# USB0_COMMON_0_VBP2APB_WRAP_CONTROLLER_VBP_CORE_ADDR_MAP register map
Vendor: Texas Instruments
Registers are 32-bit, access per field, reset 0x0 unless marked. A register's access mark holds for its fields unless they carry their own. Offsets are as the file gives them; [hi:lo] are bit positions; {n}, {i} and the like mark numbered series.

## USB0_COMMON_0_VBP2APB_WRAP_CONTROLLER_VBP_CORE_ADDR_MAP (part 7 of 8)
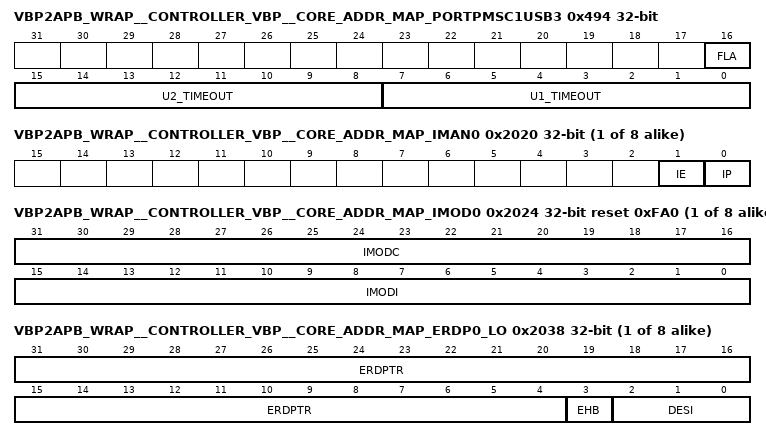
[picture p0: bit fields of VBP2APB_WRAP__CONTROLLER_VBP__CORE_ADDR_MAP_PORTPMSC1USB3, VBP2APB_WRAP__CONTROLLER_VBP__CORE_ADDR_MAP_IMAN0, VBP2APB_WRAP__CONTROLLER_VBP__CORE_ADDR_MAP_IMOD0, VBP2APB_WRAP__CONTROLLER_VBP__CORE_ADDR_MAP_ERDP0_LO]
0x494 VBP2APB_WRAP__CONTROLLER_VBP__CORE_ADDR_MAP_PORTPMSC1USB3
  [16] FLA rw — Force Link PM Accept [FLA], RW. Default = '0'. When this bit is set to '1', the port shall generate a Set Link Function LMP with the Force_LinkPM_Accept bit asserted ['1']. When this bit is cleared to '0', the port shall generate a Set Link Function LMP with the Force_LinkPM_Accept bit de-asserted ['0']. This flag shall be set to '0' by the assertion of PR to '1' or when CCS = transitions from '0' to '1'. Writes to this flag have no effect if PP = '0'. The Set Link Function LMP is sent by the xHC to the device connected on this port when this bit transitions from '0' to '1' or '1' to '0'. Refer to Sections 8.4.2 and 10.14.2.2 of the USB3 specification for more details. Improper use of the SS Force_LinkPM_Accept functionality can impact the performance of the link significantly. This bit shall only be used for compliance and testing purposes. Software shall ensure that there are no pending packets at the link level before setting this bit. This flag is '0' if PP is '0'.
  [15:8] U2_TIMEOUT rw — U2 Timeout, RWS. Default = 0. Timeout value for U2 inactivity timer. If equal to FFh, the port is disabled from initiating U2 entry. This field shall be set to '0' by the assertion of PR to '1'. Refer to section 4.19.4.1 of xHCI specification for more information on U2 Timeout operation. The following are permissible values: 00h Zero [default] 01h 256 us 02h 512 us ... FEh 65,.024 ms FFh Infinite A U2 Inactivity Timeout LMP shall be sent by the xHC to the device connected on this port when this field is written. Refer to Sections 8.4.3 and 10.4.2.10 of the USB3 specification for more details.
  [7:0] U1_TIMEOUT rw — U1 Timeout, RWS. Default = 0. Timeout value for U1 inactivity timer. If equal to FFh, the port is disabled from initiating U1 entry. This field shall be set to '0' by the assertion of PR to '1'. Refer to section 4.19.4.1 of xHCI specification for more information on U1 Timeout operation. The following are permissible values: 00h Zero [default] 01h 1 us. 02h 2 us. ... 7Fh 127 us. 80h - FEh Reserved FFh Infinite
0x498 VBP2APB_WRAP__CONTROLLER_VBP__CORE_ADDR_MAP_PORTLI1 ro
  [15:0] LEC — Link Error Count, RO. Default = '0'. This field returns the number of link errors detected by the port. This value shall be reset to '0' by the assertion of a Chip Hardware Reset, HCRST, when PR transitions from 1 to 0, or when CCS = transitions from '0' to '1'.
0x49C VBP2APB_WRAP__CONTROLLER_VBP__CORE_ADDR_MAP_RSVDP1USB3 ro
0x2000 VBP2APB_WRAP__CONTROLLER_VBP__CORE_ADDR_MAP_MFINDEX ro
  [13:0] MFINDEX — Microframe Index, RO. The value in this register increments at the end of each microframe [e.g. 125us.]. Bits [13:3] may be used to determine the current 1ms Frame Index. Note: Setting frindex_wr_en to '1' [bit 31 of XECP_CMDM_CTRL_REG3] enables software writes to this field.
0x2004 VBP2APB_WRAP__CONTROLLER_VBP__CORE_ADDR_MAP_RSVDZ_RT ro
{0x2020+0x20*i} VBP2APB_WRAP__CONTROLLER_VBP__CORE_ADDR_MAP_IMAN{i} access not given (i=0..7)
  [1] IE rw — Interrupt Enable [IE], RW. Default = '0'. This flag specifies whether the Interrupter is capable of generating an interrupt. When this bit and the IP bit are set ['1'], the Interrupter shall generate an interrupt when the Interrupter Moderation Counter reaches 0. If this bit is '0', then the Interrupter is prohibited from generating interrupts.
  [0] IP — Interrupt Pending [IP], RW1C. Default = '0'. This flag represents the current state of the Interrupter. If IP = '1', an interrupt is pending for this Interrupter. A '0' value indicates that no interrupt is pending for the Interrupter. Refer to section 4.17.5 of the xHCI specification for the conditions that modify the state of this flag. (access R/W1TC)
{0x2024+0x20*i} VBP2APB_WRAP__CONTROLLER_VBP__CORE_ADDR_MAP_IMOD{i} rw reset 0xFA0 (i=0..7)
  [31:16] IMODC — Interrupt Moderation Counter [IMODC], RW. Default = undefined. Down counter. Loaded with the IMODI value whenever IP is cleared to '0', counts down to 0, and stops. The associated interrupt shall be signaled whenever this counter is zero, the Event Ring is not empty, the IE and IP flags = '1', and EHB = '0'. This counter may be directly written by software at any time to alter the interrupt rate.
  [15:0] IMODI — Interrupt Moderation Interval [IMODI], RW. Default = 'hFA0' [~1ms]. Minimum inter-interrupt interval. The interval is specified in 250ns increments. A value of zero disables interrupt throttling logic and interrupts shall be generated immediately if IP = '0', EHB = '0', and the Event Ring is not empty. The IMODI field shall default to 'hFA0' [1 ms] upon initialization and reset. It may be loaded with an alternative value by software when the Interrupter is initialized.
{0x2028+0x20*i} VBP2APB_WRAP__CONTROLLER_VBP__CORE_ADDR_MAP_ERSTSZ{i} (i=0..7)
  [15:0] ERSTS rw — Event Ring Segment Table Size, RW. Default = 0. This field identifies the number of valid Event Ring Segment Table entries in the Event Ring Segment Table pointed to by the Event Ring Segment Table Base Address register. The maximum value supported by an xHC implementation for this register is defined by the ERST Max field in the HCSPARAMS2 register. For Secondary Interrupters: Writing a value of 0 to this field disables the Event Ring. Any events targeted at this Event Ring when it is disabled shall result in undefined behavior of the Event Ring. For the Primary Interrupter: Writing a value of 0 to this field shall result in undefined behavior of the Event Ring. The Primary Event Ring cannot be disabled.
{0x202C+0x20*i} VBP2APB_WRAP__CONTROLLER_VBP__CORE_ADDR_MAP_reserved{i} ro (i=0..7)
{0x2030+0x20*i} VBP2APB_WRAP__CONTROLLER_VBP__CORE_ADDR_MAP_ERSTBA{i}_LO (i=0..7)
  [31:6] ERSTBADDR_LO rw — Event Ring Segment Table Base Address Register, RW. Default = 0. This field defines the low order bit [25:0] of the start address of the Event Ring Segment Table [the address is 58 bits wide] . Writing this register sets the Event Ring State Machine: EREP Advancement to the Start state. This field shall not be modified if HCHalted [HCH] = '0'.
{0x2034+0x20*i} VBP2APB_WRAP__CONTROLLER_VBP__CORE_ADDR_MAP_ERSTBA{i}_HI rw (i=0..7)
  [31:0] ERSTBADDR_HI — Event Ring Segment Table Base Address Register, RW. Default = 0. This field defines the high order bits [57:26] of the start address of the Event Ring Segment Table [the address is 58 bits wide] . Writing this register sets the Event Ring State Machine:EREP Advancement to the Start state. Refer to Figure 20 in xHCI specificationfor more information. This field shall not be modified if HCHalted [HCH] = '0'.
{0x2038+0x20*i} VBP2APB_WRAP__CONTROLLER_VBP__CORE_ADDR_MAP_ERDP{i}_LO access not given (i=0..7)
  [31:4] ERDPTR rw — Event Ring Dequeue Pointer, RW. Default = 0. This field defines the 28 low order bits of the 64-bit address of the current Event Ring Dequeue Pointer.
  [3] EHB — Event Handler Busy [EHB], RW1C. Default = '0'. This flag shall be set to '1' when the IP bit is set to '1' and cleared to '0' by software when the Dequeue Pointer register is written. Refer to section 4.17.2 of xHCI specification for more information (access R/W1TC)
  [2:0] DESI rw — Dequeue ERST Segment Index [DESI]. Default = 0. This field may be used by the xHC to accelerate checking the Event Ring full condition. This field is written with the low order 3 bits of the offset of the ERST entry which defines the Event Ring segment that the Event Ring Dequeue Pointer resides in.
{0x203C+0x20*i} VBP2APB_WRAP__CONTROLLER_VBP__CORE_ADDR_MAP_ERDP{i}_HI rw (i=0..7)
  [31:0] ERDPTR_HI — Event Ring Dequeue Pointer, RW. Default = 0. This field defines the 32 high order bits of the 64-bit address of the current Event Ring Dequeue Pointer.
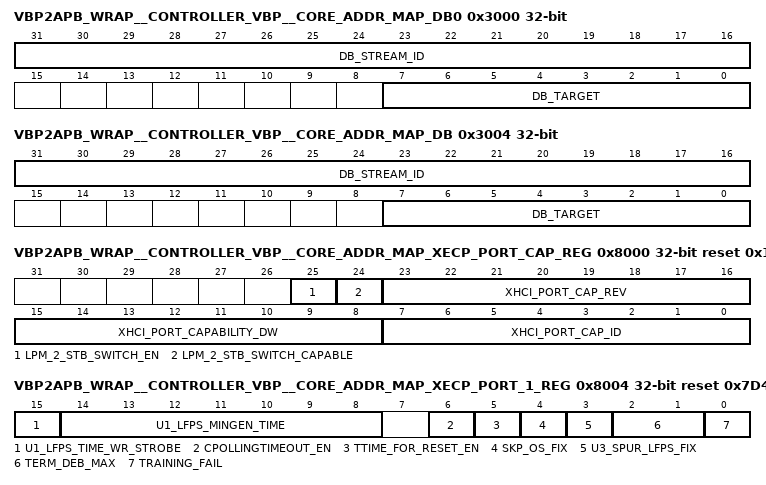
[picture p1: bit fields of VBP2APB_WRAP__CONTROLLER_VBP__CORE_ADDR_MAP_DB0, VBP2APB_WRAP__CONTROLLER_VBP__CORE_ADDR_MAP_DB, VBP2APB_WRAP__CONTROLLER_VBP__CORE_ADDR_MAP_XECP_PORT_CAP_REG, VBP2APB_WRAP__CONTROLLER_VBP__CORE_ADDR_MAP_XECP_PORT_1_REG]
0x3000 VBP2APB_WRAP__CONTROLLER_VBP__CORE_ADDR_MAP_DB0
  [31:16] DB_STREAM_ID rw — DB Stream ID, RW. Doorbell Stream ID. If the endpoint of a Device Context Doorbell defines Streams, then this field shall be used to identify which Stream of the endpoint the doorbell reference is targeting. System software is responsible for ensuring that the value written to this field is valid. If the endpoint defines Streams [MaxPStreams > 0], then 0, 65535 [No Stream] and 65534 [Prime] are reserved Stream ID values and shall not be written to this field. If the endpoint does not define Streams [MaxPStreams = 0] and a non-'0' value is written to this field, the doorbell reference shall be ignored. This field only applies to Device Context Doorbells and shall be cleared to zero for Host Controller Command Doorbells. This field returns zero when read.
  [7:0] DB_TARGET rw — DB Target, RW. Doorbell Target. This field defines the target of the doorbell reference. The table below defines the xHC notification that is generated by ringing the doorbell. Note that Doorbell Register 0 is dedicated to Command Ring and decodes this field differently than the other Doorbell Registers. Possible values [ For this register, there is only one valid value for the DB Target field, 0 [Host Controller Command]. The remaining values [1-255] are reserved.]: 0: Command Doorbell 1:247 Reserved 248:255 Vendor Defined This field returns zero when read and should be treated as undefined by software. When the Command Doorbell is written, the DB Stream ID field shall be cleared to zero.
0x3004 VBP2APB_WRAP__CONTROLLER_VBP__CORE_ADDR_MAP_DB
  [31:16] DB_STREAM_ID rw — DB Stream ID, RW. Doorbell Stream ID. If the endpoint of a Device Context Doorbell defines Streams, then this field shall be used to identify which Stream of the endpoint the doorbell reference is targeting. System software is responsible for ensuring that the value written to this field is valid. If the endpoint defines Streams [MaxPStreams > 0], then 0, 65535 [No Stream] and 65534 [Prime] are reserved Stream ID values and shall not be written to this field. If the endpoint does not define Streams [MaxPStreams = 0] and a non-'0' value is written to this field, the doorbell reference shall be ignored. This field only applies to Device Context Doorbells and shall be cleared to zero for Host Controller Command Doorbells. This field returns zero when read.
  [7:0] DB_TARGET rw — DB Target, RW. Doorbell Target. This field defines the target of the doorbell reference. The table below defines the xHC notification that is generated by ringing the doorbell. Possible values: 0: Reserved 1: Control EP 0 Enqueue Pointer Update 2: EP 1 OUT Enqueue Pointer Update 3: EP 1 IN Enqueue Pointer Update 4: EP 2 OUT Enqueue Pointer Update 5: EP 2 IN Enqueue Pointer Update ... 30: EP 15 OUT Enqueue Pointer Update 31: EP 15 IN Enqueue Pointer Update 32:247: Reserved 248:255: Vendor Defined This field returns zero when read and should be treated as undefined by software. When the Command Doorbell is written, the DB Stream ID field shall be cleared to zero.
0x8000 VBP2APB_WRAP__CONTROLLER_VBP__CORE_ADDR_MAP_XECP_PORT_CAP_REG reset 0x10102C3
  [25] LPM_2_STB_SWITCH_EN rw — Enable switching to stb_clk.
  [24] LPM_2_STB_SWITCH_CAPABLE ro — xHC is capable of switching to stb_clk.
  [23:16] XHCI_PORT_CAP_REV ro — XHCI_PORT_CAP_REV : revision of the Port Capability structure .
  [15:8] XHCI_PORT_CAPABILITY_DW ro — XHCI_PORT_CAPABILITY_DW. Next Item Pointer. This field provides an offset pointing to the location of next item in the functions capability list.
  [7:0] XHCI_PORT_CAP_ID ro — XHCI_PORT_CAP_ID. Port capability ID.
0x8004 VBP2APB_WRAP__CONTROLLER_VBP__CORE_ADDR_MAP_XECP_PORT_1_REG access not given reset 0x7D40
  [15] U1_LFPS_TIME_WR_STROBE rw — Minimum U1 LFPS generation time write stobe. Returns '0' when read.
  [14:8] U1_LFPS_MINGEN_TIME rw — Minimum U1 LFPS generation time. Written only if U1_LFPS_TIME_WR_STROBE is 1.
  [6] CPOLLINGTIMEOUT_EN rw — Enable cPollingTimeout
  [5] TTIME_FOR_RESET_EN rw — Enable tTimeForResetError timer
  [4] SKP_OS_FIX rw — Change counting number of symbols for SKP OS insertion [only for the 1st SKP OS]
  [3] U3_SPUR_LFPS_FIX rw — Enable filtering out spurious LFPS when entering U3 state
  [2:1] TERM_DEB_MAX rw — Number of the consecutive lack of Far-end Rx Termination detected that causes transition from SS.Inactive to RxDetect state
  [0] TRAINING_FAIL — When reading: Link Polling training error flag status, When writing '1': clear the Link Polling training error flag, When writing '0': no effect (access R/W1TC)
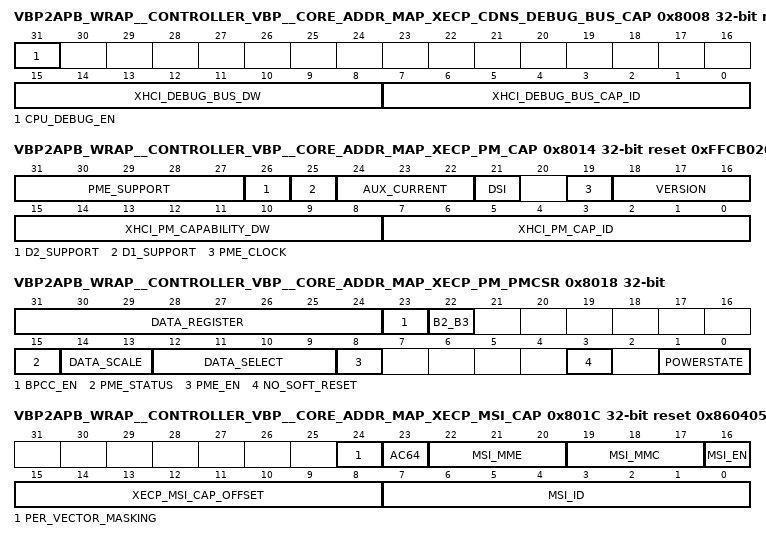
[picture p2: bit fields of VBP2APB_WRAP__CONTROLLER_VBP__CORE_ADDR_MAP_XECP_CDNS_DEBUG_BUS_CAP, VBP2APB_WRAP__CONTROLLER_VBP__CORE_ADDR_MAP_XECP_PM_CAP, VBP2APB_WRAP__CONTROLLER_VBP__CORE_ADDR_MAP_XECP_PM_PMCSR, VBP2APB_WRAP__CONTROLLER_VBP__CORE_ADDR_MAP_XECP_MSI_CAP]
0x8008 VBP2APB_WRAP__CONTROLLER_VBP__CORE_ADDR_MAP_XECP_CDNS_DEBUG_BUS_CAP reset 0x3C4
  [31] CPU_DEBUG_EN rw — Debug Bus Enable, RW. When 0, allows the xhci_debug_sel primary input to control selection of Debug Bus sources. When 1, allows the cpu_debug_bus_sel field in the XECP_CDNS_DEBUG_BUS_CTRL register to control selection of Debug Bus sources. Default value after reset is '0'.
  [15:8] XHCI_DEBUG_BUS_DW ro — Next Capability Pointer, RO. This field indicates the location of the next capability with respect to the effective address of this capability.
  [7:0] XHCI_DEBUG_BUS_CAP_ID ro — Capability ID, RO. This field identifies the extended capability. For xHCI Debug Bus its' value is 196.
0x800C VBP2APB_WRAP__CONTROLLER_VBP__CORE_ADDR_MAP_XECP_CDNS_DEBUG_BUS_CTRL
  [4:0] CPU_DEBUG_BUS_SEL rw — Debug Bus Select, RW. Value of this field determines a source of Debug Bus. Default value after reset is 0.
0x8010 VBP2APB_WRAP__CONTROLLER_VBP__CORE_ADDR_MAP_XECP_CDNS_DEBUG_BUS_STATUS ro
  [31:0] XHCI_DEBUG_BUS — Debug Bus, RO. Debug Bus current value. Note for multi-bit probes, this register is only suitable for analysing a static value due to simplified clock domain synchronisation
0x8014 VBP2APB_WRAP__CONTROLLER_VBP__CORE_ADDR_MAP_XECP_PM_CAP reset 0xFFCB0203
  [31:27] PME_SUPPORT ro — Power Management Capabilities: PME_Support. Default = device specific. This 5-bit field indicates the power states in which the function may assert PME#. A value of '0' for any bit indicates that the function is not capable of asserting the PME# signal while in that power state. Encodings: Bit 0 set: X XXX1b - PME# can be asserted from D0, Bit 1 set: X XX1Xb - PME# can be asserted from D1, Bit 2 set: X X1XXb - PME# can be asserted from D2, Bit 3 set: X 1XXXb - PME# can be asserted from D3hot, Bit 4 set: 1 XXXXb - PME# can be asserted from D3cold
  [26] D2_SUPPORT ro — Power Management Capabilities: D2_Support. Default = device specific. If this bit is a '1', this function supports the D2 Power Management State. Functions that do not support D2 must always return a value of '0' for this bit.
  [25] D1_SUPPORT ro — Power Management Capabilities: D1_Support. Default = device specific. If this bit is a '1', this function supports the D1 Power Management State. Functions that do not support D1 must always return a value of '0' for this bit.
  [24:22] AUX_CURRENT rw — Power Management Capabilities: Aux_Current. Default = device specific. This 3 bit field reports the 3.3Vaux auxiliary current requirements for the PCI function. If the Data Register field of XECP_PM_PMCSR has been implemented by this function: - reads of this field must return a value of '000', - the Data Register takes precedence over this field for 3.3Vaux current requirement reporting. If PME# generation from D3cold is not supported by the Function [XECP_PM_CAP[15]='0'], this field must return a value of '000' when read. For functions that support PME# from D3cold, and do not implement the Data Register, the following bit encoding for maximum current required apply : '111': 375 mA, '110': 320 mA, '101': 270 mA, '100': 220 mA, '011': 160 mA, '010': 100 mA, '001': 55 mA, '000': 0 [self powered].
  [21] DSI ro — Power Management Capabilities: DSI. Default = device specific. The Device Specific Initialization bit indicates whether special initialization of this function is required [beyond the standard PCI configuration header] before the generic class device driver is able to use it. Note that this bit is not used by some operating systems. Microsoft Windows and Windows NT, for instance, do not use this bit to determine whether to use D3. Instead, they use the drivers capabilities to determine this. A '1' indicates that the function requires a device specific initialization sequence following transition to the D0 uninitialized state. For more information refer to Section 8.3. of PCI bus Power Management specification.
  [19] PME_CLOCK ro — Power Management Capabilities: PME Clock. Default = '0'. When this bit is a '1', it indicates that the function relies on the presence of the PCI clock for PME# operation. When this bit is a '0', it indicates that no PCI clock is required for the function to generate PME#. Functions that do not support PME# generation in any state must return '0' for this field.
  [18:16] VERSION ro — Power Management Capabilities: Version. Default = '011'. A value of '011' indicates that this function complies with revision 1.2 of the PCI Power Management Interface Specification.
  [15:8] XHCI_PM_CAPABILITY_DW ro — XHCI_PM_CAPABILITY_DW. Next Item Pointer. This field provides an offset pointing to the location of next item in the functions capability list.
  [7:0] XHCI_PM_CAP_ID ro — XHCI_PM_CAP_ID. Power Management capability ID.
0x8018 VBP2APB_WRAP__CONTROLLER_VBP__CORE_ADDR_MAP_XECP_PM_PMCSR access not given
  [31:24] DATA_REGISTER ro — Data register. This register is used to report the state dependent data requested by the Data_Select field of XECP_PM_PMCSR register. The value of Data register is scaled by the value reported by the Data_Scale field of XECP_PM_PMCSR register.
  [23] BPCC_EN ro — PMCSR Bridge Support Extensions: BPCC_En [Bus Power/Clock Control Enable]. External strap or internally hardwired. A '1' indicates that the bus power/clock control mechanism as defined in Section 4.7.1 PCI bus Power Management specification is enabled. A '0' indicates that the bus power/clock control policies defined in Section 4.7.1 PCI bus Power Management specification have been disabled. When the Bus Power/Clock Control mechanism is disabled, the bridges Power Management Control/Status Register PowerState field cannot be used by the system software to control the power or clock of the bridges secondary bus.
  [22] B2_B3 ro — PMCSR Bridge Support Extensions: B2_B3# [B2/B3 support for D3hot]. External strap or internally hardwired. The state of this bit determines the action that is to occur as a direct result of programming the function to D3hot. A '1' indicates that when the bridge function is programmed to D3hot, its secondary buss PCI clock will be stopped [B2]. A '0' indicates that when the bridge function is programmed to D3hot, its secondary bus will have its power removed [B3]. This bit is only meaningful if bit BPCC_En of XECP_PM_PMCSR register is a '1'. Refer to Section 4.7.1 of PCI bus Power Management specification for details.
  [15] PME_STATUS — Power Management Control/Status Register: PME_Status. This bit is set when the function would normally assert the PME# signal independent of the state of the PME_En bit. Writing a '1' to this bit will clear it and cause the function to stop asserting a PME# [if enabled]. Writing a '0' has no effect. This bit defaults to '0' if the function does not support PME# generation from D3cold. If the function supports PME# from D3cold, then this bit is sticky and must be explicitly cleared by the operating system each time the operating system is initially loaded. (access R/W1TC)
  [14:13] DATA_SCALE ro — Power Management Control/Status Register: Data_Scale. Default = device specific. This 2-bit read-only field indicates the scaling factor to be used when interpreting the value of the Data register field of XECP_PM_PMCSR register. The value and meaning of this field will vary depending on which data value has been selected by the Data_Select field of this register. This field is a required component of the Data register and must be implemented if the Data register is implemented. If the Data register has not been implemented, this field must return zero when read. Refer to Section 3.2.6 of PCI bus Power Management specification for more details.
  [12:9] DATA_SELECT rw — Power Management Control/Status Register: Data_Select. Default = zero. This 4-bit field is used to select, which data is to be reported through the Data register and Data_Scale fields of XECP_PM_PMCSR register. This field is a required component of the Data register and must be implemented if the Data register is implemented. If the Data register field of XECP_PM_PMCSR is not implemented, this field should be read only and return zero when read. Refer to Section 3.2.6 of PCI bus Power Management for more details.
  [8] PME_EN rw — Power Management Control/Status Register: PME_En. A '1' in this field enables the function to assert PME#. When '0', PME# assertion is disabled. This bit defaults to '0' if the function does not support PME# generation from D3cold. If the function supports PME# from D3cold, then this bit is sticky and must be explicitly cleared by the operating system each time it is initially loaded. Functions that do not support PME# generation from any D-state [i.e., XECP_PM_CAP[15:11] = '00000'], may hardwire this bit to be read-only always returning a '0' when read by system software.
  [3] NO_SOFT_RESET ro — Power Management Control/Status Register: No_Soft_Reset. Default = device specific. When set to '1', this bit indicates that devices transitioning from D3hot to D0 because of PowerState commands do not perform an internal reset. Configuration Context is preserved. Upon transition from the D3hot to the D0 Initialized state, no additional operating system intervention is required to preserve Configuration Context beyond writing the PowerState bits. When cleared to '0', devices do perform an internal reset upon transitioning from D3hot to D0 via software control of the PowerState bits. Configuration Context is lost when performing the soft reset. Upon transition from the D3hot to the D0 state, full reinitialization sequence is needed to return the device to D0 Initialized. Regardless of this bit, devices that transition from D3hot to D0 by a system or bus segment reset will return to the device state D0 Uninitialized with only PME context preserved if PME is supported and enabled.
  [1:0] POWERSTATE rw — Power Management Control/Status Register: PowerState. Default = zero. This 2-bit field is used both to determine the current power state of a function and to set the function into a new power state. Possible values: '00': D0, '01': D1, '10': D2, '11': D3hot. If software attempts to write an unsupported, optional state to this field, the write operation must complete normally on the bus. however, the data is discarded and no state change occurs.
0x801C VBP2APB_WRAP__CONTROLLER_VBP__CORE_ADDR_MAP_XECP_MSI_CAP reset 0x860405
  [24] PER_VECTOR_MASKING ro — MSI Message Control: Per-vector masking capable. If '1', the function supports MSI per-vector masking. If '0', the function does not support MSI per-vector masking. This bit is read only. Not Supported in this configuration
  [23] AC64 ro — MSI Message Control: 64 bit address capable. If '1', the function is capable of generating sending a 64-bit message address. If '0', the function is not capable of generating sending a 64-bit message address. This bit is read only.
  [22:20] MSI_MME rw — MSI Message Control: Multiple Message Enable. Software writes to this field to indicate the number of allocated vectors [equal to or less than the number of requested vectors]. The number of allocated vectors is aligned to a power of two. If a function requests four vectors [indicated by a Multiple Message Capable encoding of 010], system software can allocate either four, two, or one vector by writing a '010', '001', or '000' to this field, respectively. When MSI is enabled, a function will be allocated at least one vector. The encoding is defined as: '000': 1, '001': 2, '010': 4, '011': 8, '100': 16, '101': 32, '110': Reserved, '111': Reserved. This fields state after reset is '000'.
  [19:17] MSI_MMC ro — MSI Message Control: Multiple Message Capable. System software reads this field to determine the number of requested vectors. The number of requested vectors must be aligned to a power of two [if a function requires three vectors, it requests four by initializing this field to '010']. The encoding is defined as: '000': 1, '001': 2, '010': 4, '011': 8, '100': 16, '101': 32, '110': Reserved, '111': Reserved. This field is read only.
  [16] MSI_EN rw — MSI Message Control: MSI enable. System configuration software sets this bit to enable MSI. A device driver is prohibited from writing this bit to mask a functions service request. If '0', the function is prohibited from using MSI to request service. This bits state after reset is '0' [MSI is disabled].
  [15:8] XECP_MSI_CAP_OFFSET ro — Pointer to the next item in the capabilities list. A non-zero value in this field indicates a relative offset, in 32-bit words, from this 32-bit word to the beginning of the next extended capability.
  [7:0] MSI_ID ro — Capability ID for Message Signaled Interrupts. The value of 05h in this field identifies the function as being MSI capable.
0x8020 VBP2APB_WRAP__CONTROLLER_VBP__CORE_ADDR_MAP_XECP_MSI_ADDR_L access not given
  [31:2] MSI_ADDR_LOW rw — Message Lower Address for MSI. System-specified message address. If the Message Enable bit of MSI Message Control [bit 16 of the XCEP_MSI_CAP register] is set, the contents of this register specify the DWORD-aligned address for the MSI memory write transaction. Note: This field should not be written unless the Message Enable bit of MSI Message Control [bit 16 of the XCEP_MSI_CAP register] is cleared. This field is read/write.
0x8024 VBP2APB_WRAP__CONTROLLER_VBP__CORE_ADDR_MAP_XECP_MSI_ADDR_H rw
  [31:0] MSI_ADDR_HI — Message Upper Address for MSI. System-specified message upper address. Note: This field should not be written unless the Message Enable bit of MSI Message Control [bit 16 of the XCEP_MSI_CAP register] is cleared. This field is read/write.
0x8028 VBP2APB_WRAP__CONTROLLER_VBP__CORE_ADDR_MAP_XECP_MSI_DATA
  [15:0] MSI_DATA rw — System-specified message data. If the Message Enable bit of MSI Message Control [bit 16 of the XCEP_MSI_CAP register] is set, the message data is driven onto the lower word [bits [15:0]] of the memory write transactions data phase. Bits [31:16] are driven to zero during the memory write transactions data phase. C/BE[3::0]# are asserted during the data phase of the memory write transaction. The Multiple Message Enable field of MSI Message Control [see MSI_MME field of XCEP_MSI_CAP register] defines the number of low order message data bits the function is permitted to modify to generate its system software allocated vectors. For example, a Multiple Message Enable encoding of '010' indicates the function has been allocated four vectors and is permitted to modify message data bits 1 and 0 [a function modifies the lower message data bits to generate the allocated number of vectors]. If the Multiple Message Enable field is '000', the function is not permitted to modify the message data. Note: This field should not be written unless the Message Enable bit of MSI Message Control [bit 16 of the XCEP_MSI_CAP register] is cleared. This field is read/write.
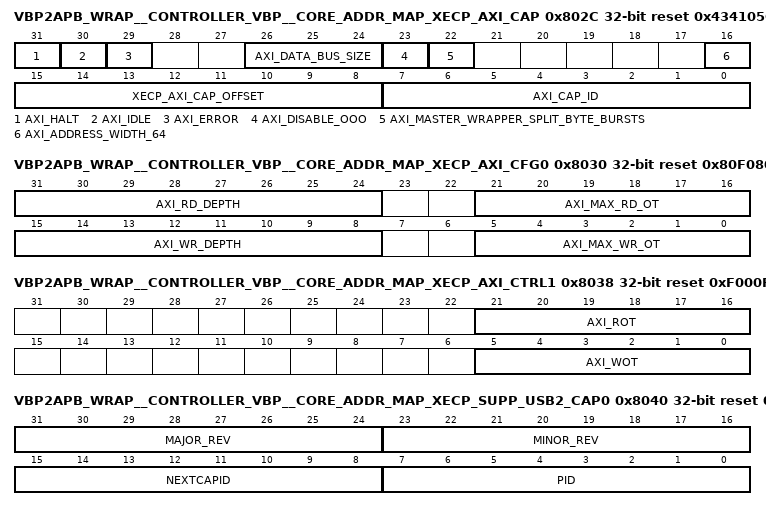
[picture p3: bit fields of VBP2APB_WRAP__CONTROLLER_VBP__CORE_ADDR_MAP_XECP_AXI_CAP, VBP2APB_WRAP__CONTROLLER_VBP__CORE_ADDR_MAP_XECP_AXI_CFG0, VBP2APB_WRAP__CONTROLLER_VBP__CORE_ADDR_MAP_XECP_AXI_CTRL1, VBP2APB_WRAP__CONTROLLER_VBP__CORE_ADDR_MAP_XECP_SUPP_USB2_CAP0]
0x802C VBP2APB_WRAP__CONTROLLER_VBP__CORE_ADDR_MAP_XECP_AXI_CAP access not given reset 0x434105C2
  [31] AXI_HALT rw — AXI HALT, RW. The AXI Master wrapper's control bit. When set, the AXI Master wrapper will complete current CORE REQ [or IRQ] and stop acknowledging next ones. If the xHC is stopped the AXI Master wrapper is halted automatically. If the xHC is started the AXI Master wrapper is resumed automatically. Software should set this bit to stop the AXI Master issuing new AXI transactions. It may then use the IDLE bit to determine when all previous transactions were completed. Note: The AXI Master wrapper will execute halted only if xHC stopped its internal operation.
  [30] AXI_IDLE ro — AXI IDLE, RO. Information about the AXI Master wrapper state: '0': no pending action required by the AXI Master wrapper, '1': the AXI Master wrapper has outstanding transactions. Note: HCH halted bit will not be asserted if the AXI Master wrapper is not idle.
  [29] AXI_ERROR — AXI ERROR, RW1C. Provides an information about AXI ERROR response on B or R channel. This flag is cleared by writing '1' to it. Once set it is held until cleared. The condition setting this register will also assert HSE. This flag may be read by software while handling HSE assertion to determine if the case was AXI ERROR reponse. (access R/W1TC)
  [26:24] AXI_DATA_BUS_SIZE ro — AXI_DATA_WORD_SIZE, RO. AXI data buses size capability. It uses AXI AxSIZE Encoding. Values of 64-bit ['011'] or 128-bit ['100'] are supported through compile time configuration.
  [23] AXI_DISABLE_OOO ro — Disable Out-Of-Order R channel responses [AXI_MASTER_WRAPPER_DISABLE_OOO], RO. This relates to number of IDs used at AXI IF. If Out-Of-Order R channel responses are not disabled this count may be greater than one and in such a case the R channel responses may come Out-Of-Order. The flag gives information about number of used AXI IDs: '0': single ID, '1': multiple IDs.
  [22] AXI_MASTER_WRAPPER_SPLIT_BYTE_BURSTS ro — AXI_MASTER_WRAPPER_SPLIT_BYTE_BURSTS, RO. Presents information about AXI byte burst capability: '0': no byte bursts, '1': byte bursts enabled.
  [16] AXI_ADDRESS_WIDTH_64 ro — AXI address bus width capability, RO. '0': 32-bit address bus width, '1': 64-bit address bus width.
  [15:8] XECP_AXI_CAP_OFFSET ro — Next capability Offset, RO. This field points to the xHC MMIO space offset of the next xHCI extended capability pointer. A value of 00h indicates the end of the extended capability list. A non-zero value in this register indicates a relative offset, in Dwords, from this Dword to the beginning of the next extended capability.
  [7:0] AXI_CAP_ID ro — VEND_DEF_AXI_MASTER_WRAPPER_CAP_ID, RO. Vendor defined xHCI Extended Capability: 0xC2. This field identifies the AXI wrapper xHCI Extended capability.
0x8030 VBP2APB_WRAP__CONTROLLER_VBP__CORE_ADDR_MAP_XECP_AXI_CFG0 ro reset 0x80F080F
  [31:24] AXI_RD_DEPTH — AXI READ_BUFFER_DEPTH, RO. Number of AXI Read beats that can be buffered by the AXI Master wrapper. The value written to this field should be the Number of AXI Read beats that can be buffered by the AXI Master wrapper minus 1.
  [21:16] AXI_MAX_RD_OT — AXI MAX_READ_OUTSTANDING, RO. Maximum number of Outstanding Read Transactions initiated by the AXI Master wrapper in AR channel. The value written to this field should be the Maximum number of Outstanding Read Transactions initiated by the AXI Master wrapper minus 1, thus the Maximum number of Outstanding Read Transactions is 1 more than the programmed value.
  [15:8] AXI_WR_DEPTH — AXI WRITE_BUFFER_DEPTH, RO. Number of AXI Write beats that can be buffered by the AXI Master wrapper. The value written to this field should be the number of AXI Write beats that can be buffered by the AXI Master wrapper minus 1.
  [5:0] AXI_MAX_WR_OT — AXI MAX_WRITE_OUTSTANDING, RO. Maximum number of Outstanding Write Transactions initiated by the AXI Master wrapper in AW channel. The value written to this field should be the Maximum number of Outstanding Write Transactions initiated by the AXI Master wrapper minus 1, thus the Maximum number of Outstanding Write Transactions is 1 more than the programmed value.
0x8034 VBP2APB_WRAP__CONTROLLER_VBP__CORE_ADDR_MAP_XECP_AXI_CTRL0 reset 0xF
  [3:0] AXI_BMAX rw — AXI BMAX, RW. The register controls maximum burst length - it is used by the AXI Master wrapper to determine maximum value of AxLEN. It uses AXI AxLEN encoding. Default value is the maximum supported one and it is implementation specific. Writing value greater than maximum will result in setting the register to its defaults. This register can be written only when the AXI Master wrapper is halted [AXI_HALT set to '1'] and idle [AXI_IDLE is '1']. Note: This register should only be written to during the register initialisation process
0x8038 VBP2APB_WRAP__CONTROLLER_VBP__CORE_ADDR_MAP_XECP_AXI_CTRL1 reset 0xF000F
  [21:16] AXI_ROT rw — AXI READ_OUTSTANDING, RW. Number of outstanding read transactions that can be initiated by the AXI Master wrapper. Default value of this field is MAX_READ_OUTSTANDING-1 [see AXI_MAX_RD_OT field of XECP_AXI_CFG0 register]. Writing value greater than the default will result in setting the register to its defaults. This register can be written only when the AXI Master wrapper is halted [AXI_HALT set to '1'] and idle [AXI_IDLE is '1']. The value written to this field should be the requested number of outstanding read transactions minus 1, thus the actual number of possible outstanding read transactions is one more than the programmed value. Note: This register should only be written to during the register initialisation process
  [5:0] AXI_WOT rw — AXI WRITE_OUTSTANDING, RW. Number of outstanding write transactions that can be initiated by the AXI Master wrapper. Default value of this field is MAX_WRITE_OUTSTANDING-1 [see AXI_MAX_WR_OT field of XECP_AXI_CFG0]. Writing value greater than the default will result in setting the register to its defaults. This register can be written only when the AXI Master wrapper is halted [AXI_HALT set to '1'] and idle [AXI_IDLE is '1']. The value written to this field should be the requested number of outstanding write transactions minus 1, thus the actual number of possible outstanding write transactions is one more than the programmed value. Note: This register should only be written to during the register initialisation process
0x803C VBP2APB_WRAP__CONTROLLER_VBP__CORE_ADDR_MAP_XECP_AXI_CTRL2 reset 0x1
  [7:0] AXI_WTHRES rw — AXI Write Buffer Threshold, RW. When performing an AXI write burst this field specifies the minimum number of required AXI beats buffered prior to starting the burst on AXI W-Channel by asserting wvalid. This allows a user to balance the requirement for minimal latency with the requirement for low bus utilisation during bursts. Burst lengths smaller than or equal to this threshold will be buffered completely and then output on W-Channel. Burst lengths greater than this threshold will output the burst on the W-Channel such that the first AXI_WTHRES beats will be continuously with no drop of WVALID, beats thereafter may or may not be continuous depending on availability of data. Legal values are between 1 and [AXI_WDD-1]. A value of 1 means that the burst is started on W-Channel as soon as any data is available without any additional delay. A value of 0 is reserved and should not be used as may lead to unpredictable behaviour. This register can be written only when the AXI Master wrapper is halted [AXI_HALT set to '1'] and idle [AXI_IDLE is '1']. Note: This register should only be written to during the register initialisation process.
0x8040 VBP2APB_WRAP__CONTROLLER_VBP__CORE_ADDR_MAP_XECP_SUPP_USB2_CAP0 ro reset 0x2000802
  [31:24] MAJOR_REV — Major Specification Release Number in Binary-Coded Decimal [i.e.,version 3.x is 03h]. This field identifies the major release number component of the specification with which the xHC is compliant.
  [23:16] MINOR_REV — Minor Specification Release Number in Binary-Coded Decimal [i.e.,version x.10 is 10h]. This field identifies the minor release number component of the specification with which the xHC is compliant.
  [15:8] NEXTCAPID — This field indicates the location of the next capability with respect to the effective address of this capability. Refer to Table 142 of xHCI specification for more information on this field.
  [7:0] PID — Capability ID. The value identifies the capability as Supported Protocol.
0x8044 VBP2APB_WRAP__CONTROLLER_VBP__CORE_ADDR_MAP_XECP_SUPP_USB2_CAP1 ro reset 0x20425355
  [31:0] USB_STRING — Name String, RO. This field is a mnemonic name string that references the specification with which the xHC is compliant. Four ASCII characters may be defined. Allowed characters are: alphanumeric, space, and underscore. Alpha characters are case sensitive. Refer to section 7.2.2 of xHCI specification for defined values.
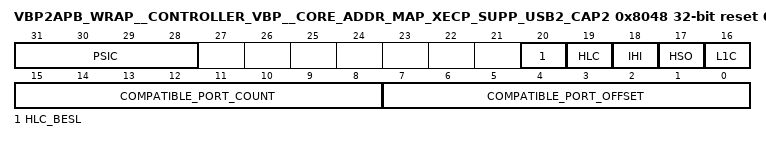
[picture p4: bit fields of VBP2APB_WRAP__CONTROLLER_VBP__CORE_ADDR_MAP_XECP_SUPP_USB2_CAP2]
0x8048 VBP2APB_WRAP__CONTROLLER_VBP__CORE_ADDR_MAP_XECP_SUPP_USB2_CAP2 ro reset 0x30190101
  [31:28] PSIC — Protocol Speed ID Count: 3, USB 2.0 Speed [High, Full, Low]. This field indicates the number of Protocol Speed ID [PSI] Dwords that the xHCI Supported Protocol Capability data structure contains. If this field is non-zero, then all speeds supported by the protocol shall be defined using PSI Dwords, i.e. no implied Speed ID mappings apply.
  [20] HLC_BESL — HLC_BESL. In xHCI 1.0 specification this field is reserved RsvdP, see section 7.2.2.1.3. The field is described in xHCI 1.1 specification: BESL LPM Capability [BLC], RO. Default = Implementation dependent. If this bit is set to '1', the ports described by this xHCI Supported Protocol Capability shall apply BESL timing to BESL and BESLD fields of the PORTPMSC and PORTHLPMC registers, as defined in Table 13. If this bit is cleared to '0', the ports described by this xHCI Supported Protocol Capability shall apply HIRD timing to BESL and BESLD fields of the PORTPMSC and PORTHLPMC registers, as defined in Table 13. Refer to section 4.23.5.1.1.1 for more information. Note the BESL LMP Capability support [i.e. HLE = 1 and BLC = 1] shall be mandatory for all xHCI 1.1 compliant xHCs.
  [19] HLC — Hardware LPM Capability. Default = Implementation dependent. If this bit is set to '1', the ports described by this xHCI Supported Protocol Capability support hardware controlled USB2 Link Power Management. Refer to section 4.23.5.1.1.1 of xHCI specification.
  [18] IHI — Integrated Hub Implemented. Default = Implementation dependent. If this bit is cleared to '0', the Root Hub to External xHC port mapping adheres to the default mapping described in section 4.24.2.1 of xHCI specification. If this bit is set to '1', the Root Hub to External xHC port mapping does not adhere to the default mapping described in section 4.24.2.1 of xHCI specification, and an ACPI or other mechanism is required to define the mapping.
  [17] HSO — High-speed Only. Default = Implementation dependent. If this bit is cleared to '0', the USB2 ports described by this capability are Low-, Full-, and High-speed capable. If this bit is set to '1', the USB2 ports described by this capability are High-speed only, e.g. the ports do not support Low- or Full-speed operation. High-speed only implementations may introduce a Tier mismatch, refer to section 4.24.2 of xHCI specification for more information.
  [16] L1C — If '1'LPM is supported [mandatory in xHCI1_00]. In xHCI specification this field is reserved RsvdP, see section 7.2.2.1.3
  [15:8] COMPATIBLE_PORT_COUNT — This field identifies the number of consecutive Root Hub Ports [starting at the Compatible Port Offset] that support this protocol. Valid values are 1 to MaxPorts.
  [7:0] COMPATIBLE_PORT_OFFSET — This field specifies the starting Port Number of Root Hub Ports that support this protocol. Valid values are 1 to MaxPorts.
0x804C VBP2APB_WRAP__CONTROLLER_VBP__CORE_ADDR_MAP_XECP_SUPP_USB2_PROTOCOL_SLOT_TYPE ro
  [4:0] PST — This field specifies the Protocol Slot Type value, which may be specified when allocating Device Slots that support this protocol. Valid values are 0 to 31. Refer to sections 4.6.3 and 7.2.2.1.4 of xHCI specification. The value of the Protocol Slot Type field declared by a xHCI Supported Protocol Capability structure is unique to an xHC implementation. Software shall not assume a fixed mapping of the Protocol Slot Type value to a specific type of Supported Protocol. Note that for compatibility reasons, the Protocol Slot Type value of 0 is the exception to this rule and reserved for the USB Protocol Device Slot type.
